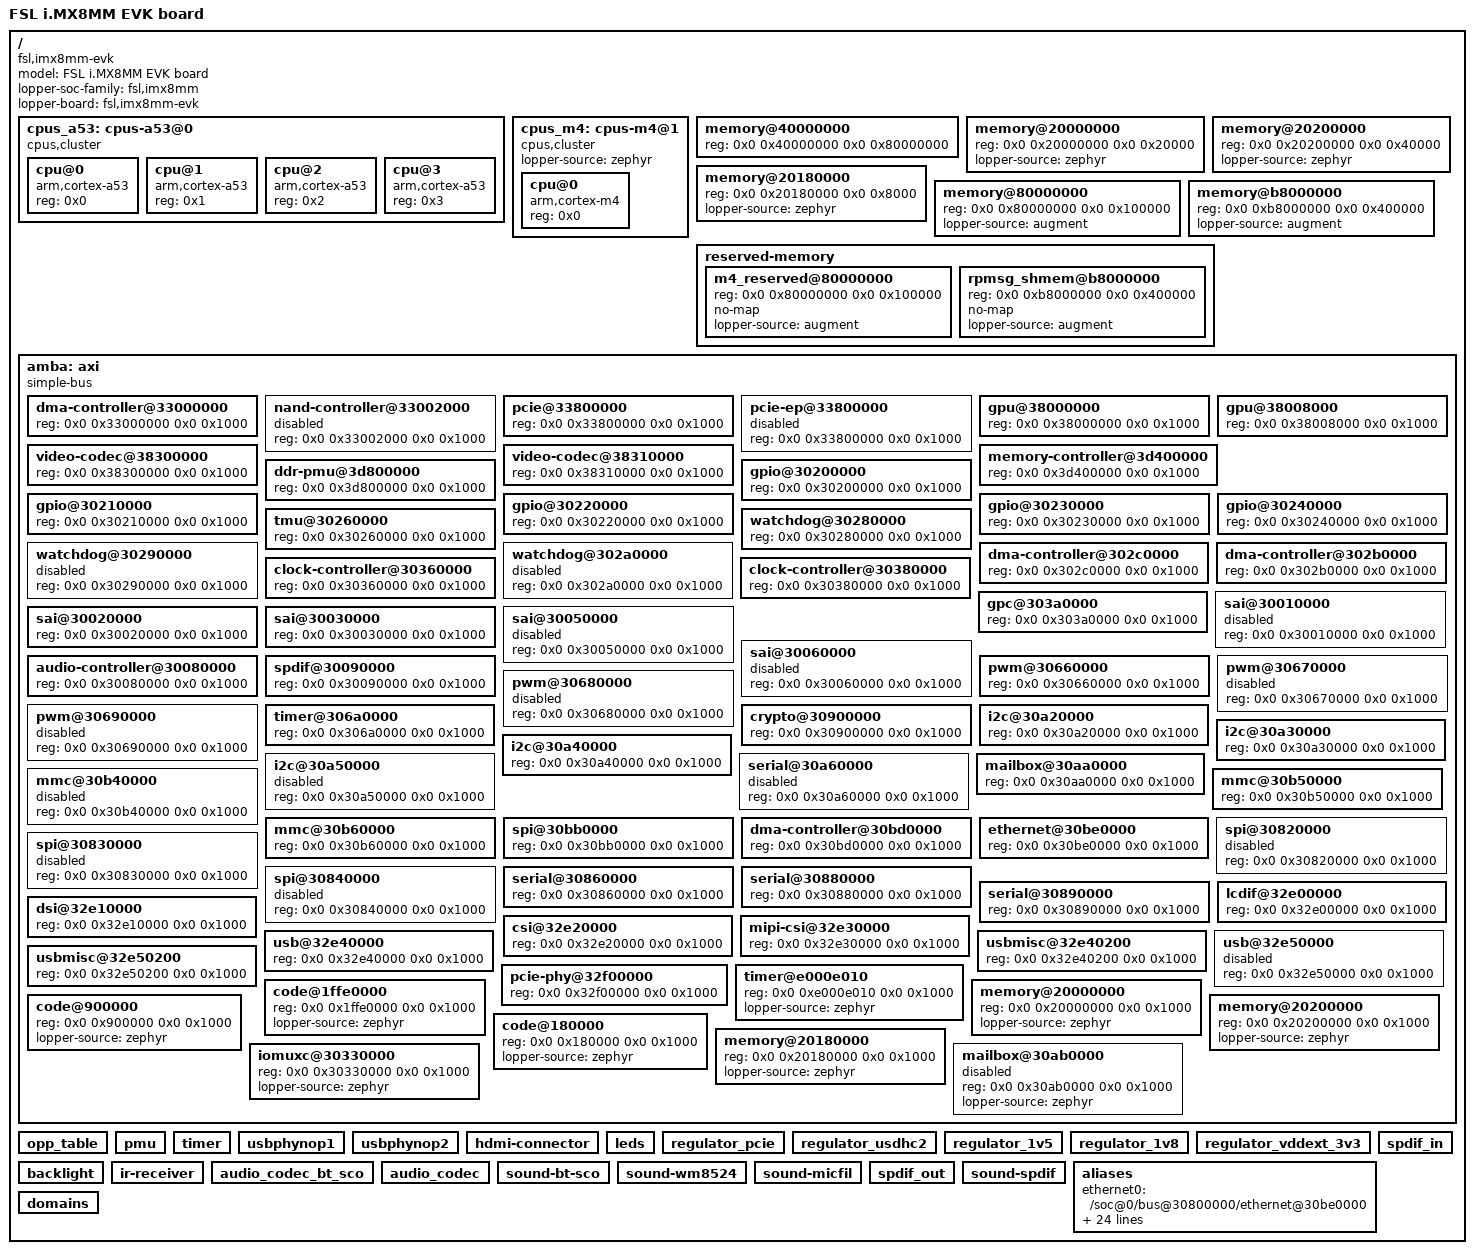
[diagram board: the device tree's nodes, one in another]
/dts-v1/;

/*
 * AUTO-GENERATED by lopper assemble_sdt from a compose_devices
 * devices YAML. Do NOT edit this file by hand — re-run the pipeline
 * with the appropriate inputs (Linux DT + optional Zephyr DT +
 * per-board augment.yaml) to regenerate.
 *
 * This is a System Device Tree intermediate. Per-device detail
 * (clocks, interrupts, vendor properties) is not reproduced from the
 * source DTs in this MVP — peripheral nodes are stubs carrying just
 * the inventory facts (reg, status, source tag, pm_node, bootph).
 * Downstream tooling (lopper domain assists) consumes this as input
 * to produce per-OS device trees.
 */

/ {
    #address-cells = <2>;
    #size-cells = <2>;
    compatible = "fsl,imx8mm-evk", "fsl,imx8mm";
    model = "FSL i.MX8MM EVK board";
    lopper-soc-family = "fsl,imx8mm";
    lopper-board = "fsl,imx8mm-evk";

    cpus_a53: cpus-a53@0 {
        #address-cells = <1>;
        #size-cells = <0>;
        compatible = "cpus,cluster";

        cpu@0 {
            device_type = "cpu";
            compatible = "arm,cortex-a53";
            reg = <0x0>;
        };

        cpu@1 {
            device_type = "cpu";
            compatible = "arm,cortex-a53";
            reg = <0x1>;
        };

        cpu@2 {
            device_type = "cpu";
            compatible = "arm,cortex-a53";
            reg = <0x2>;
        };

        cpu@3 {
            device_type = "cpu";
            compatible = "arm,cortex-a53";
            reg = <0x3>;
        };
    };

    cpus_m4: cpus-m4@1 {
        #address-cells = <1>;
        #size-cells = <0>;
        compatible = "cpus,cluster";
        lopper-source = "zephyr";

        cpu@0 {
            device_type = "cpu";
            compatible = "arm,cortex-m4";
            reg = <0x0>;
        };
    };

    memory@40000000 {
        device_type = "memory";
        reg = <0x0 0x40000000 0x0 0x80000000>;
    };

    memory@20000000 {
        device_type = "memory";
        reg = <0x0 0x20000000 0x0 0x20000>;
        lopper-source = "zephyr";
    };

    memory@20200000 {
        device_type = "memory";
        reg = <0x0 0x20200000 0x0 0x40000>;
        lopper-source = "zephyr";
    };

    memory@20180000 {
        device_type = "memory";
        reg = <0x0 0x20180000 0x0 0x8000>;
        lopper-source = "zephyr";
    };

    memory@80000000 {
        device_type = "memory";
        reg = <0x0 0x80000000 0x0 0x100000>;
        lopper-source = "augment";
    };

    memory@b8000000 {
        device_type = "memory";
        reg = <0x0 0xb8000000 0x0 0x400000>;
        lopper-source = "augment";
    };

    reserved-memory {
        #address-cells = <2>;
        #size-cells = <2>;
        ranges;

        m4_reserved@80000000 {
            reg = <0x0 0x80000000 0x0 0x100000>;
            no-map;
            lopper-source = "augment";
        };

        rpmsg_shmem@b8000000 {
            reg = <0x0 0xb8000000 0x0 0x400000>;
            no-map;
            lopper-source = "augment";
        };
    };

    amba: axi {
        compatible = "simple-bus";
        #address-cells = <2>;
        #size-cells = <2>;
        ranges;

        dma-controller@33000000 {
            reg = <0x0 0x33000000 0x0 0x1000>;
            /* label = dma_controller33000000 */
        };

        nand-controller@33002000 {
            reg = <0x0 0x33002000 0x0 0x1000>;
            status = "disabled";
        };

        pcie@33800000 {
            reg = <0x0 0x33800000 0x0 0x1000>;
        };

        pcie-ep@33800000 {
            reg = <0x0 0x33800000 0x0 0x1000>;
            status = "disabled";
        };

        gpu@38000000 {
            reg = <0x0 0x38000000 0x0 0x1000>;
        };

        gpu@38008000 {
            reg = <0x0 0x38008000 0x0 0x1000>;
        };

        video-codec@38300000 {
            reg = <0x0 0x38300000 0x0 0x1000>;
        };

        video-codec@38310000 {
            reg = <0x0 0x38310000 0x0 0x1000>;
        };

        memory-controller@3d400000 {
            reg = <0x0 0x3d400000 0x0 0x1000>;
        };

        ddr-pmu@3d800000 {
            reg = <0x0 0x3d800000 0x0 0x1000>;
        };

        gpio@30200000 {
            reg = <0x0 0x30200000 0x0 0x1000>;
            /* label = gpio30200000 */
        };

        gpio@30210000 {
            reg = <0x0 0x30210000 0x0 0x1000>;
            /* label = gpio30210000 */
        };

        gpio@30220000 {
            reg = <0x0 0x30220000 0x0 0x1000>;
            /* label = gpio30220000 */
        };

        gpio@30230000 {
            reg = <0x0 0x30230000 0x0 0x1000>;
            /* label = gpio30230000 */
        };

        gpio@30240000 {
            reg = <0x0 0x30240000 0x0 0x1000>;
        };

        tmu@30260000 {
            reg = <0x0 0x30260000 0x0 0x1000>;
            /* label = tmu30260000 */
        };

        watchdog@30280000 {
            reg = <0x0 0x30280000 0x0 0x1000>;
        };

        watchdog@30290000 {
            reg = <0x0 0x30290000 0x0 0x1000>;
            status = "disabled";
        };

        watchdog@302a0000 {
            reg = <0x0 0x302a0000 0x0 0x1000>;
            status = "disabled";
        };

        dma-controller@302c0000 {
            reg = <0x0 0x302c0000 0x0 0x1000>;
            /* label = dma_controller302c0000 */
        };

        dma-controller@302b0000 {
            reg = <0x0 0x302b0000 0x0 0x1000>;
        };

        clock-controller@30360000 {
            reg = <0x0 0x30360000 0x0 0x1000>;
        };

        clock-controller@30380000 {
            reg = <0x0 0x30380000 0x0 0x1000>;
            /* label = clock_controller30380000_1 */
        };

        gpc@303a0000 {
            reg = <0x0 0x303a0000 0x0 0x1000>;
        };

        sai@30010000 {
            reg = <0x0 0x30010000 0x0 0x1000>;
            status = "disabled";
        };

        sai@30020000 {
            reg = <0x0 0x30020000 0x0 0x1000>;
            /* label = sai30020000 */
        };

        sai@30030000 {
            reg = <0x0 0x30030000 0x0 0x1000>;
            /* label = sai30030000 */
        };

        sai@30050000 {
            reg = <0x0 0x30050000 0x0 0x1000>;
            status = "disabled";
        };

        sai@30060000 {
            reg = <0x0 0x30060000 0x0 0x1000>;
            status = "disabled";
        };

        audio-controller@30080000 {
            reg = <0x0 0x30080000 0x0 0x1000>;
            /* label = audio_controller30080000 */
        };

        spdif@30090000 {
            reg = <0x0 0x30090000 0x0 0x1000>;
            /* label = spdif30090000 */
        };

        pwm@30660000 {
            reg = <0x0 0x30660000 0x0 0x1000>;
        };

        pwm@30670000 {
            reg = <0x0 0x30670000 0x0 0x1000>;
            status = "disabled";
        };

        pwm@30680000 {
            reg = <0x0 0x30680000 0x0 0x1000>;
            status = "disabled";
        };

        pwm@30690000 {
            reg = <0x0 0x30690000 0x0 0x1000>;
            status = "disabled";
        };

        timer@306a0000 {
            reg = <0x0 0x306a0000 0x0 0x1000>;
        };

        crypto@30900000 {
            reg = <0x0 0x30900000 0x0 0x1000>;
        };

        i2c@30a20000 {
            reg = <0x0 0x30a20000 0x0 0x1000>;
        };

        i2c@30a30000 {
            reg = <0x0 0x30a30000 0x0 0x1000>;
        };

        i2c@30a40000 {
            reg = <0x0 0x30a40000 0x0 0x1000>;
        };

        i2c@30a50000 {
            reg = <0x0 0x30a50000 0x0 0x1000>;
            status = "disabled";
        };

        serial@30a60000 {
            reg = <0x0 0x30a60000 0x0 0x1000>;
            status = "disabled";
        };

        mailbox@30aa0000 {
            reg = <0x0 0x30aa0000 0x0 0x1000>;
        };

        mmc@30b40000 {
            reg = <0x0 0x30b40000 0x0 0x1000>;
            status = "disabled";
        };

        mmc@30b50000 {
            reg = <0x0 0x30b50000 0x0 0x1000>;
        };

        mmc@30b60000 {
            reg = <0x0 0x30b60000 0x0 0x1000>;
        };

        spi@30bb0000 {
            reg = <0x0 0x30bb0000 0x0 0x1000>;
        };

        dma-controller@30bd0000 {
            reg = <0x0 0x30bd0000 0x0 0x1000>;
            /* label = dma_controller30bd0000 */
        };

        ethernet@30be0000 {
            reg = <0x0 0x30be0000 0x0 0x1000>;
        };

        spi@30820000 {
            reg = <0x0 0x30820000 0x0 0x1000>;
            status = "disabled";
        };

        spi@30830000 {
            reg = <0x0 0x30830000 0x0 0x1000>;
            status = "disabled";
        };

        spi@30840000 {
            reg = <0x0 0x30840000 0x0 0x1000>;
            status = "disabled";
        };

        serial@30860000 {
            reg = <0x0 0x30860000 0x0 0x1000>;
        };

        serial@30880000 {
            reg = <0x0 0x30880000 0x0 0x1000>;
        };

        serial@30890000 {
            reg = <0x0 0x30890000 0x0 0x1000>;
        };

        lcdif@32e00000 {
            reg = <0x0 0x32e00000 0x0 0x1000>;
        };

        dsi@32e10000 {
            reg = <0x0 0x32e10000 0x0 0x1000>;
        };

        csi@32e20000 {
            reg = <0x0 0x32e20000 0x0 0x1000>;
        };

        mipi-csi@32e30000 {
            reg = <0x0 0x32e30000 0x0 0x1000>;
        };

        usb@32e40000 {
            reg = <0x0 0x32e40000 0x0 0x1000>;
        };

        usbmisc@32e40200 {
            reg = <0x0 0x32e40200 0x0 0x1000>;
            /* label = usbmisc32e40200 */
        };

        usb@32e50000 {
            reg = <0x0 0x32e50000 0x0 0x1000>;
            status = "disabled";
        };

        usbmisc@32e50200 {
            reg = <0x0 0x32e50200 0x0 0x1000>;
            /* label = usbmisc32e50200 */
        };

        pcie-phy@32f00000 {
            reg = <0x0 0x32f00000 0x0 0x1000>;
            /* label = pcie_phy32f00000 */
        };

        timer@e000e010 {
            reg = <0x0 0xe000e010 0x0 0x1000>;
            lopper-source = "zephyr";
        };

        code@1ffe0000 {
            reg = <0x0 0x1ffe0000 0x0 0x1000>;
            lopper-source = "zephyr";
        };

        memory@20000000 {
            reg = <0x0 0x20000000 0x0 0x1000>;
            lopper-source = "zephyr";
        };

        code@900000 {
            reg = <0x0 0x900000 0x0 0x1000>;
            lopper-source = "zephyr";
        };

        memory@20200000 {
            reg = <0x0 0x20200000 0x0 0x1000>;
            lopper-source = "zephyr";
        };

        code@180000 {
            reg = <0x0 0x180000 0x0 0x1000>;
            lopper-source = "zephyr";
        };

        memory@20180000 {
            reg = <0x0 0x20180000 0x0 0x1000>;
            lopper-source = "zephyr";
        };

        iomuxc@30330000 {
            reg = <0x0 0x30330000 0x0 0x1000>;
            lopper-source = "zephyr";
        };

        mailbox@30ab0000 {
            reg = <0x0 0x30ab0000 0x0 0x1000>;
            status = "disabled";
            lopper-source = "zephyr";
        };
    };

    opp_table {
        /* label = opp_table */
    };

    pmu {
    };

    timer {
    };

    usbphynop1 {
        /* label = usbphynop1 */
    };

    usbphynop2 {
        /* label = usbphynop2 */
    };

    hdmi-connector {
    };

    leds {
    };

    regulator_pcie {
        /* label = regulator_pcie */
    };

    regulator_usdhc2 {
        /* label = regulator_usdhc2 */
    };

    regulator_1v5 {
        /* label = regulator_1v5 */
    };

    regulator_1v8 {
        /* label = regulator_1v8 */
    };

    regulator_vddext_3v3 {
        /* label = regulator_vddext_3v3 */
    };

    backlight {
    };

    ir-receiver {
    };

    audio_codec_bt_sco {
        /* label = audio_codec_bt_sco */
    };

    audio_codec {
        /* label = audio_codec */
    };

    sound-bt-sco {
    };

    sound-wm8524 {
    };

    sound-micfil {
    };

    spdif_out {
        /* label = spdif_out */
    };

    spdif_in {
        /* label = spdif_in */
    };

    sound-spdif {
    };

    aliases {
        ethernet0 = "/soc@0/bus@30800000/ethernet@30be0000";
        gpio0 = "/soc@0/bus@30000000/gpio@30200000";
        gpio1 = "/soc@0/bus@30000000/gpio@30210000";
        gpio2 = "/soc@0/bus@30000000/gpio@30220000";
        gpio3 = "/soc@0/bus@30000000/gpio@30230000";
        gpio4 = "/soc@0/bus@30000000/gpio@30240000";
        i2c0 = "/soc@0/bus@30800000/i2c@30a20000";
        i2c1 = "/soc@0/bus@30800000/i2c@30a30000";
        i2c2 = "/soc@0/bus@30800000/i2c@30a40000";
        i2c3 = "/soc@0/bus@30800000/i2c@30a50000";
        mmc0 = "/soc@0/bus@30800000/mmc@30b40000";
        mmc1 = "/soc@0/bus@30800000/mmc@30b50000";
        mmc2 = "/soc@0/bus@30800000/mmc@30b60000";
        serial0 = "/soc@0/bus@30800000/spba-bus@30800000/serial@30860000";
        serial1 = "/soc@0/bus@30800000/spba-bus@30800000/serial@30890000";
        serial2 = "/soc@0/bus@30800000/spba-bus@30800000/serial@30880000";
        serial3 = "/soc@0/bus@30800000/serial@30a60000";
        spi0 = "/soc@0/bus@30800000/spi@30bb0000";
        spi1 = "/soc@0/bus@30800000/spba-bus@30800000/spi@30830000";
        spi2 = "/soc@0/bus@30800000/spba-bus@30800000/spi@30840000";
    };

    domains {
        #address-cells = <2>;
        #size-cells = <2>;
        /* Partition intent goes here. Populate via openamp,domain-v1
         * YAML overlays processed by Lopper's existing domain assists. */
    };

};
